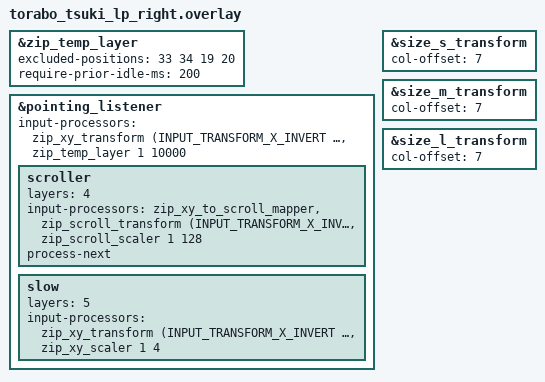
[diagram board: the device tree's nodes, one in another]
#include "torabo_tsuki_lp.dtsi"
#include <input/processors.dtsi>
#include <dt-bindings/zmk/input_transform.h>

&zip_temp_layer {
    excluded-positions = <
        33 // J
        34 // K
        19 // u
        20 // I
    >;
};

&zip_temp_layer {
    require-prior-idle-ms = <200>;
};

// 
&pointing_listener {
    input-processors = <&zip_xy_transform (INPUT_TRANSFORM_X_INVERT | INPUT_TRANSFORM_Y_INVERT)>, <&zip_temp_layer 1 10000>;
    scroller {
        layers = <4>;
        input-processors = <&zip_xy_to_scroll_mapper>, <&zip_scroll_transform (INPUT_TRANSFORM_X_INVERT)>, <&zip_scroll_scaler 1 128>;
        process-next;
    };
    slow {
        layers = <5>;
        input-processors = <&zip_xy_transform (INPUT_TRANSFORM_X_INVERT | INPUT_TRANSFORM_Y_INVERT)>, <&zip_xy_scaler 1 4>;
    };
};


&size_s_transform {
    col-offset = <7>;
};

&size_m_transform {
    col-offset = <7>;
};

&size_l_transform {
    col-offset = <7>;
};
